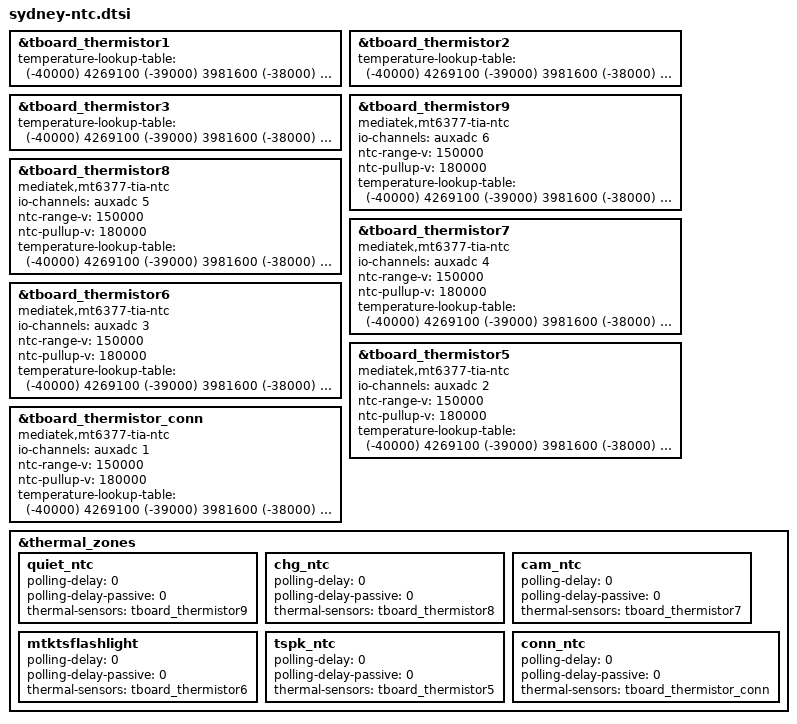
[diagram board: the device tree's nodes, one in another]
/*[TN.NJDC] ntc overlay file.start*/
&tboard_thermistor1 {
	temperature-lookup-table = <
		(-40000) 4269100
		(-39000) 3981600
		(-38000) 3715100
		(-37000) 3468000
		(-36000) 3238600
		(-35000) 3025700
		(-34000) 2827900
		(-33000) 2644200
		(-32000) 2473400
		(-31000) 2314600
		(-30000) 2166900
		(-29000) 2029400
		(-28000) 1901400
		(-27000) 1782200
		(-26000) 1671100
		(-25000) 1567500
		(-24000) 1471000
		(-23000) 1380900
		(-22000) 1296900
		(-21000) 1218400
		(-20000) 1145100
		(-19000) 1076600
		(-18000) 1012600
		(-17000) 952790
		(-16000) 896810
		(-15000) 844440
		(-14000) 795410
		(-13000) 749510
		(-12000) 706500
		(-11000) 666200
		(-10000) 628430
		(-9000) 593000
		(-8000) 559770
		(-7000) 528580
		(-6000) 499300
		(-5000) 471810
		(-4000) 445980
		(-3000) 421710
		(-2000) 398890
		(-1000) 377440
		0 357250
		1000 338260
		2000 320380
		3000 303540
		4000 287680
		5000 272740
		6000 258650
		7000 245370
		8000 232850
		9000 221030
		10000 209870
		11000 199340
		12000 189400
		13000 180010
		14000 171130
		15000 162740
		16000 154800
		17000 147300
		18000 140200
		19000 133480
		20000 127120
		21000 121090
		22000 115390
		23000 109980
		24000 104860
		25000 100000
		26000 95393
		27000 91023
		28000 86877
		29000 82941
		30000 79205
		31000 75656
		32000 72286
		33000 69083
		34000 66039
		35000 63146
		36000 60394
		37000 57776
		38000 55286
		39000 52916
		40000 50660
		41000 48512
		42000 46466
		43000 44517
		44000 42660
		45000 40889
		46000 39202
		47000 37592
		48000 36057
		49000 34592
		50000 33195
		51000 31860
		52000 30587
		53000 29370
		54000 28208
		55000 27098
		56000 26037
		57000 25023
		58000 24053
		59000 23126
		60000 22239
		61000 21390
		62000 20578
		63000 19801
		64000 19056
		65000 18344
		66000 17661
		67000 17007
		68000 16381
		69000 15780
		70000 15205
		71000 14653
		72000 14124
		73000 13616
		74000 13129
		75000 12662
		76000 12213
		77000 11782
		78000 11369
		79000 10972
		80000 10591
		81000 10224
		82000 9872
		83000 9533
		84000 9208
		85000 8895
		86000 8595
		87000 8305
		88000 8027
		89000 7760
		90000 7502
		91000 7254
		92000 7015
		93000 6785
		94000 6564
		95000 6351
		96000 6146
		97000 5948
		98000 5757
		99000 5573
		100000 5396
		101000 5225
		102000 5061
		103000 4902
		104000 4749
		105000 4601
		106000 4458
		107000 4321
		108000 4188
		109000 4059
		110000 3936
		111000 3816
		112000 3700
		113000 3589
		114000 3481
		115000 3377
		116000 3276
		117000 3179
		118000 3085
		119000 2994
		120000 2906
		121000 2821
		122000 2739
		123000 2659
		124000 2582
		125000 2508>;
};
&tboard_thermistor2 {
	temperature-lookup-table = <
		(-40000) 4269100
		(-39000) 3981600
		(-38000) 3715100
		(-37000) 3468000
		(-36000) 3238600
		(-35000) 3025700
		(-34000) 2827900
		(-33000) 2644200
		(-32000) 2473400
		(-31000) 2314600
		(-30000) 2166900
		(-29000) 2029400
		(-28000) 1901400
		(-27000) 1782200
		(-26000) 1671100
		(-25000) 1567500
		(-24000) 1471000
		(-23000) 1380900
		(-22000) 1296900
		(-21000) 1218400
		(-20000) 1145100
		(-19000) 1076600
		(-18000) 1012600
		(-17000) 952790
		(-16000) 896810
		(-15000) 844440
		(-14000) 795410
		(-13000) 749510
		(-12000) 706500
		(-11000) 666200
		(-10000) 628430
		(-9000) 593000
		(-8000) 559770
		(-7000) 528580
		(-6000) 499300
		(-5000) 471810
		(-4000) 445980
		(-3000) 421710
		(-2000) 398890
		(-1000) 377440
		0 357250
		1000 338260
		2000 320380
		3000 303540
		4000 287680
		5000 272740
		6000 258650
		7000 245370
		8000 232850
		9000 221030
		10000 209870
		11000 199340
		12000 189400
		13000 180010
		14000 171130
		15000 162740
		16000 154800
		17000 147300
		18000 140200
		19000 133480
		20000 127120
		21000 121090
		22000 115390
		23000 109980
		24000 104860
		25000 100000
		26000 95393
		27000 91023
		28000 86877
		29000 82941
		30000 79205
		31000 75656
		32000 72286
		33000 69083
		34000 66039
		35000 63146
		36000 60394
		37000 57776
		38000 55286
		39000 52916
		40000 50660
		41000 48512
		42000 46466
		43000 44517
		44000 42660
		45000 40889
		46000 39202
		47000 37592
		48000 36057
		49000 34592
		50000 33195
		51000 31860
		52000 30587
		53000 29370
		54000 28208
		55000 27098
		56000 26037
		57000 25023
		58000 24053
		59000 23126
		60000 22239
		61000 21390
		62000 20578
		63000 19801
		64000 19056
		65000 18344
		66000 17661
		67000 17007
		68000 16381
		69000 15780
		70000 15205
		71000 14653
		72000 14124
		73000 13616
		74000 13129
		75000 12662
		76000 12213
		77000 11782
		78000 11369
		79000 10972
		80000 10591
		81000 10224
		82000 9872
		83000 9533
		84000 9208
		85000 8895
		86000 8595
		87000 8305
		88000 8027
		89000 7760
		90000 7502
		91000 7254
		92000 7015
		93000 6785
		94000 6564
		95000 6351
		96000 6146
		97000 5948
		98000 5757
		99000 5573
		100000 5396
		101000 5225
		102000 5061
		103000 4902
		104000 4749
		105000 4601
		106000 4458
		107000 4321
		108000 4188
		109000 4059
		110000 3936
		111000 3816
		112000 3700
		113000 3589
		114000 3481
		115000 3377
		116000 3276
		117000 3179
		118000 3085
		119000 2994
		120000 2906
		121000 2821
		122000 2739
		123000 2659
		124000 2582
		125000 2508>;
};
&tboard_thermistor3 {
	temperature-lookup-table = <
		(-40000) 4269100
		(-39000) 3981600
		(-38000) 3715100
		(-37000) 3468000
		(-36000) 3238600
		(-35000) 3025700
		(-34000) 2827900
		(-33000) 2644200
		(-32000) 2473400
		(-31000) 2314600
		(-30000) 2166900
		(-29000) 2029400
		(-28000) 1901400
		(-27000) 1782200
		(-26000) 1671100
		(-25000) 1567500
		(-24000) 1471000
		(-23000) 1380900
		(-22000) 1296900
		(-21000) 1218400
		(-20000) 1145100
		(-19000) 1076600
		(-18000) 1012600
		(-17000) 952790
		(-16000) 896810
		(-15000) 844440
		(-14000) 795410
		(-13000) 749510
		(-12000) 706500
		(-11000) 666200
		(-10000) 628430
		(-9000) 593000
		(-8000) 559770
		(-7000) 528580
		(-6000) 499300
		(-5000) 471810
		(-4000) 445980
		(-3000) 421710
		(-2000) 398890
		(-1000) 377440
		0 357250
		1000 338260
		2000 320380
		3000 303540
		4000 287680
		5000 272740
		6000 258650
		7000 245370
		8000 232850
		9000 221030
		10000 209870
		11000 199340
		12000 189400
		13000 180010
		14000 171130
		15000 162740
		16000 154800
		17000 147300
		18000 140200
		19000 133480
		20000 127120
		21000 121090
		22000 115390
		23000 109980
		24000 104860
		25000 100000
		26000 95393
		27000 91023
		28000 86877
		29000 82941
		30000 79205
		31000 75656
		32000 72286
		33000 69083
		34000 66039
		35000 63146
		36000 60394
		37000 57776
		38000 55286
		39000 52916
		40000 50660
		41000 48512
		42000 46466
		43000 44517
		44000 42660
		45000 40889
		46000 39202
		47000 37592
		48000 36057
		49000 34592
		50000 33195
		51000 31860
		52000 30587
		53000 29370
		54000 28208
		55000 27098
		56000 26037
		57000 25023
		58000 24053
		59000 23126
		60000 22239
		61000 21390
		62000 20578
		63000 19801
		64000 19056
		65000 18344
		66000 17661
		67000 17007
		68000 16381
		69000 15780
		70000 15205
		71000 14653
		72000 14124
		73000 13616
		74000 13129
		75000 12662
		76000 12213
		77000 11782
		78000 11369
		79000 10972
		80000 10591
		81000 10224
		82000 9872
		83000 9533
		84000 9208
		85000 8895
		86000 8595
		87000 8305
		88000 8027
		89000 7760
		90000 7502
		91000 7254
		92000 7015
		93000 6785
		94000 6564
		95000 6351
		96000 6146
		97000 5948
		98000 5757
		99000 5573
		100000 5396
		101000 5225
		102000 5061
		103000 4902
		104000 4749
		105000 4601
		106000 4458
		107000 4321
		108000 4188
		109000 4059
		110000 3936
		111000 3816
		112000 3700
		113000 3589
		114000 3481
		115000 3377
		116000 3276
		117000 3179
		118000 3085
		119000 2994
		120000 2906
		121000 2821
		122000 2739
		123000 2659
		124000 2582
		125000 2508>;
};
&tboard_thermistor9 {
	compatible = "mediatek,mt6377-tia-ntc";
	io-channels = <&auxadc 6>;
	io-channel-names = "QUIET_NTC";
	ntc-range-v = <150000>;
	ntc-pullup-v = <180000>;
	#thermal-sensor-cells = <0>;
	temperature-lookup-table = <
		(-40000) 4269100
		(-39000) 3981600
		(-38000) 3715100
		(-37000) 3468000
		(-36000) 3238600
		(-35000) 3025700
		(-34000) 2827900
		(-33000) 2644200
		(-32000) 2473400
		(-31000) 2314600
		(-30000) 2166900
		(-29000) 2029400
		(-28000) 1901400
		(-27000) 1782200
		(-26000) 1671100
		(-25000) 1567500
		(-24000) 1471000
		(-23000) 1380900
		(-22000) 1296900
		(-21000) 1218400
		(-20000) 1145100
		(-19000) 1076600
		(-18000) 1012600
		(-17000) 952790
		(-16000) 896810
		(-15000) 844440
		(-14000) 795410
		(-13000) 749510
		(-12000) 706500
		(-11000) 666200
		(-10000) 628430
		(-9000) 593000
		(-8000) 559770
		(-7000) 528580
		(-6000) 499300
		(-5000) 471810
		(-4000) 445980
		(-3000) 421710
		(-2000) 398890
		(-1000) 377440
		0 357250
		1000 338260
		2000 320380
		3000 303540
		4000 287680
		5000 272740
		6000 258650
		7000 245370
		8000 232850
		9000 221030
		10000 209870
		11000 199340
		12000 189400
		13000 180010
		14000 171130
		15000 162740
		16000 154800
		17000 147300
		18000 140200
		19000 133480
		20000 127120
		21000 121090
		22000 115390
		23000 109980
		24000 104860
		25000 100000
		26000 95393
		27000 91023
		28000 86877
		29000 82941
		30000 79205
		31000 75656
		32000 72286
		33000 69083
		34000 66039
		35000 63146
		36000 60394
		37000 57776
		38000 55286
		39000 52916
		40000 50660
		41000 48512
		42000 46466
		43000 44517
		44000 42660
		45000 40889
		46000 39202
		47000 37592
		48000 36057
		49000 34592
		50000 33195
		51000 31860
		52000 30587
		53000 29370
		54000 28208
		55000 27098
		56000 26037
		57000 25023
		58000 24053
		59000 23126
		60000 22239
		61000 21390
		62000 20578
		63000 19801
		64000 19056
		65000 18344
		66000 17661
		67000 17007
		68000 16381
		69000 15780
		70000 15205
		71000 14653
		72000 14124
		73000 13616
		74000 13129
		75000 12662
		76000 12213
		77000 11782
		78000 11369
		79000 10972
		80000 10591
		81000 10224
		82000 9872
		83000 9533
		84000 9208
		85000 8895
		86000 8595
		87000 8305
		88000 8027
		89000 7760
		90000 7502
		91000 7254
		92000 7015
		93000 6785
		94000 6564
		95000 6351
		96000 6146
		97000 5948
		98000 5757
		99000 5573
		100000 5396
		101000 5225
		102000 5061
		103000 4902
		104000 4749
		105000 4601
		106000 4458
		107000 4321
		108000 4188
		109000 4059
		110000 3936
		111000 3816
		112000 3700
		113000 3589
		114000 3481
		115000 3377
		116000 3276
		117000 3179
		118000 3085
		119000 2994
		120000 2906
		121000 2821
		122000 2739
		123000 2659
		124000 2582
		125000 2508>;
};
&tboard_thermistor8 {
	compatible = "mediatek,mt6377-tia-ntc";
	io-channels = <&auxadc 5>;
	io-channel-names = "CHG_NTC";
	ntc-range-v = <150000>;
	ntc-pullup-v = <180000>;
	#thermal-sensor-cells = <0>;
	temperature-lookup-table = <
		(-40000) 4269100
		(-39000) 3981600
		(-38000) 3715100
		(-37000) 3468000
		(-36000) 3238600
		(-35000) 3025700
		(-34000) 2827900
		(-33000) 2644200
		(-32000) 2473400
		(-31000) 2314600
		(-30000) 2166900
		(-29000) 2029400
		(-28000) 1901400
		(-27000) 1782200
		(-26000) 1671100
		(-25000) 1567500
		(-24000) 1471000
		(-23000) 1380900
		(-22000) 1296900
		(-21000) 1218400
		(-20000) 1145100
		(-19000) 1076600
		(-18000) 1012600
		(-17000) 952790
		(-16000) 896810
		(-15000) 844440
		(-14000) 795410
		(-13000) 749510
		(-12000) 706500
		(-11000) 666200
		(-10000) 628430
		(-9000) 593000
		(-8000) 559770
		(-7000) 528580
		(-6000) 499300
		(-5000) 471810
		(-4000) 445980
		(-3000) 421710
		(-2000) 398890
		(-1000) 377440
		0 357250
		1000 338260
		2000 320380
		3000 303540
		4000 287680
		5000 272740
		6000 258650
		7000 245370
		8000 232850
		9000 221030
		10000 209870
		11000 199340
		12000 189400
		13000 180010
		14000 171130
		15000 162740
		16000 154800
		17000 147300
		18000 140200
		19000 133480
		20000 127120
		21000 121090
		22000 115390
		23000 109980
		24000 104860
		25000 100000
		26000 95393
		27000 91023
		28000 86877
		29000 82941
		30000 79205
		31000 75656
		32000 72286
		33000 69083
		34000 66039
		35000 63146
		36000 60394
		37000 57776
		38000 55286
		39000 52916
		40000 50660
		41000 48512
		42000 46466
		43000 44517
		44000 42660
		45000 40889
		46000 39202
		47000 37592
		48000 36057
		49000 34592
		50000 33195
		51000 31860
		52000 30587
		53000 29370
		54000 28208
		55000 27098
		56000 26037
		57000 25023
		58000 24053
		59000 23126
		60000 22239
		61000 21390
		62000 20578
		63000 19801
		64000 19056
		65000 18344
		66000 17661
		67000 17007
		68000 16381
		69000 15780
		70000 15205
		71000 14653
		72000 14124
		73000 13616
		74000 13129
		75000 12662
		76000 12213
		77000 11782
		78000 11369
		79000 10972
		80000 10591
		81000 10224
		82000 9872
		83000 9533
		84000 9208
		85000 8895
		86000 8595
		87000 8305
		88000 8027
		89000 7760
		90000 7502
		91000 7254
		92000 7015
		93000 6785
		94000 6564
		95000 6351
		96000 6146
		97000 5948
		98000 5757
		99000 5573
		100000 5396
		101000 5225
		102000 5061
		103000 4902
		104000 4749
		105000 4601
		106000 4458
		107000 4321
		108000 4188
		109000 4059
		110000 3936
		111000 3816
		112000 3700
		113000 3589
		114000 3481
		115000 3377
		116000 3276
		117000 3179
		118000 3085
		119000 2994
		120000 2906
		121000 2821
		122000 2739
		123000 2659
		124000 2582
		125000 2508>;
};
&tboard_thermistor7 {
	compatible = "mediatek,mt6377-tia-ntc";
	io-channels = <&auxadc 4>;
	io-channel-names = "CAM_NTC";
	ntc-range-v = <150000>;
	ntc-pullup-v = <180000>;
	#thermal-sensor-cells = <0>;
	temperature-lookup-table = <
		(-40000) 4269100
		(-39000) 3981600
		(-38000) 3715100
		(-37000) 3468000
		(-36000) 3238600
		(-35000) 3025700
		(-34000) 2827900
		(-33000) 2644200
		(-32000) 2473400
		(-31000) 2314600
		(-30000) 2166900
		(-29000) 2029400
		(-28000) 1901400
		(-27000) 1782200
		(-26000) 1671100
		(-25000) 1567500
		(-24000) 1471000
		(-23000) 1380900
		(-22000) 1296900
		(-21000) 1218400
		(-20000) 1145100
		(-19000) 1076600
		(-18000) 1012600
		(-17000) 952790
		(-16000) 896810
		(-15000) 844440
		(-14000) 795410
		(-13000) 749510
		(-12000) 706500
		(-11000) 666200
		(-10000) 628430
		(-9000) 593000
		(-8000) 559770
		(-7000) 528580
		(-6000) 499300
		(-5000) 471810
		(-4000) 445980
		(-3000) 421710
		(-2000) 398890
		(-1000) 377440
		0 357250
		1000 338260
		2000 320380
		3000 303540
		4000 287680
		5000 272740
		6000 258650
		7000 245370
		8000 232850
		9000 221030
		10000 209870
		11000 199340
		12000 189400
		13000 180010
		14000 171130
		15000 162740
		16000 154800
		17000 147300
		18000 140200
		19000 133480
		20000 127120
		21000 121090
		22000 115390
		23000 109980
		24000 104860
		25000 100000
		26000 95393
		27000 91023
		28000 86877
		29000 82941
		30000 79205
		31000 75656
		32000 72286
		33000 69083
		34000 66039
		35000 63146
		36000 60394
		37000 57776
		38000 55286
		39000 52916
		40000 50660
		41000 48512
		42000 46466
		43000 44517
		44000 42660
		45000 40889
		46000 39202
		47000 37592
		48000 36057
		49000 34592
		50000 33195
		51000 31860
		52000 30587
		53000 29370
		54000 28208
		55000 27098
		56000 26037
		57000 25023
		58000 24053
		59000 23126
		60000 22239
		61000 21390
		62000 20578
		63000 19801
		64000 19056
		65000 18344
		66000 17661
		67000 17007
		68000 16381
		69000 15780
		70000 15205
		71000 14653
		72000 14124
		73000 13616
		74000 13129
		75000 12662
		76000 12213
		77000 11782
		78000 11369
		79000 10972
		80000 10591
		81000 10224
		82000 9872
		83000 9533
		84000 9208
		85000 8895
		86000 8595
		87000 8305
		88000 8027
		89000 7760
		90000 7502
		91000 7254
		92000 7015
		93000 6785
		94000 6564
		95000 6351
		96000 6146
		97000 5948
		98000 5757
		99000 5573
		100000 5396
		101000 5225
		102000 5061
		103000 4902
		104000 4749
		105000 4601
		106000 4458
		107000 4321
		108000 4188
		109000 4059
		110000 3936
		111000 3816
		112000 3700
		113000 3589
		114000 3481
		115000 3377
		116000 3276
		117000 3179
		118000 3085
		119000 2994
		120000 2906
		121000 2821
		122000 2739
		123000 2659
		124000 2582
		125000 2508>;
};
&tboard_thermistor6 {
	compatible = "mediatek,mt6377-tia-ntc";
	io-channels = <&auxadc 3>;
	io-channel-names = "FLASH_NTC";
	ntc-range-v = <150000>;
	ntc-pullup-v = <180000>;
	#thermal-sensor-cells = <0>;
	temperature-lookup-table = <
		(-40000) 4269100
		(-39000) 3981600
		(-38000) 3715100
		(-37000) 3468000
		(-36000) 3238600
		(-35000) 3025700
		(-34000) 2827900
		(-33000) 2644200
		(-32000) 2473400
		(-31000) 2314600
		(-30000) 2166900
		(-29000) 2029400
		(-28000) 1901400
		(-27000) 1782200
		(-26000) 1671100
		(-25000) 1567500
		(-24000) 1471000
		(-23000) 1380900
		(-22000) 1296900
		(-21000) 1218400
		(-20000) 1145100
		(-19000) 1076600
		(-18000) 1012600
		(-17000) 952790
		(-16000) 896810
		(-15000) 844440
		(-14000) 795410
		(-13000) 749510
		(-12000) 706500
		(-11000) 666200
		(-10000) 628430
		(-9000) 593000
		(-8000) 559770
		(-7000) 528580
		(-6000) 499300
		(-5000) 471810
		(-4000) 445980
		(-3000) 421710
		(-2000) 398890
		(-1000) 377440
		0 357250
		1000 338260
		2000 320380
		3000 303540
		4000 287680
		5000 272740
		6000 258650
		7000 245370
		8000 232850
		9000 221030
		10000 209870
		11000 199340
		12000 189400
		13000 180010
		14000 171130
		15000 162740
		16000 154800
		17000 147300
		18000 140200
		19000 133480
		20000 127120
		21000 121090
		22000 115390
		23000 109980
		24000 104860
		25000 100000
		26000 95393
		27000 91023
		28000 86877
		29000 82941
		30000 79205
		31000 75656
		32000 72286
		33000 69083
		34000 66039
		35000 63146
		36000 60394
		37000 57776
		38000 55286
		39000 52916
		40000 50660
		41000 48512
		42000 46466
		43000 44517
		44000 42660
		45000 40889
		46000 39202
		47000 37592
		48000 36057
		49000 34592
		50000 33195
		51000 31860
		52000 30587
		53000 29370
		54000 28208
		55000 27098
		56000 26037
		57000 25023
		58000 24053
		59000 23126
		60000 22239
		61000 21390
		62000 20578
		63000 19801
		64000 19056
		65000 18344
		66000 17661
		67000 17007
		68000 16381
		69000 15780
		70000 15205
		71000 14653
		72000 14124
		73000 13616
		74000 13129
		75000 12662
		76000 12213
		77000 11782
		78000 11369
		79000 10972
		80000 10591
		81000 10224
		82000 9872
		83000 9533
		84000 9208
		85000 8895
		86000 8595
		87000 8305
		88000 8027
		89000 7760
		90000 7502
		91000 7254
		92000 7015
		93000 6785
		94000 6564
		95000 6351
		96000 6146
		97000 5948
		98000 5757
		99000 5573
		100000 5396
		101000 5225
		102000 5061
		103000 4902
		104000 4749
		105000 4601
		106000 4458
		107000 4321
		108000 4188
		109000 4059
		110000 3936
		111000 3816
		112000 3700
		113000 3589
		114000 3481
		115000 3377
		116000 3276
		117000 3179
		118000 3085
		119000 2994
		120000 2906
		121000 2821
		122000 2739
		123000 2659
		124000 2582
		125000 2508>;
};
&tboard_thermistor5 {
	compatible = "mediatek,mt6377-tia-ntc";
	io-channels = <&auxadc 2>;
	io-channel-names = "SPK_NTC";
	ntc-range-v = <150000>;
	ntc-pullup-v = <180000>;
	#thermal-sensor-cells = <0>;
	temperature-lookup-table = <
		(-40000) 4269100
		(-39000) 3981600
		(-38000) 3715100
		(-37000) 3468000
		(-36000) 3238600
		(-35000) 3025700
		(-34000) 2827900
		(-33000) 2644200
		(-32000) 2473400
		(-31000) 2314600
		(-30000) 2166900
		(-29000) 2029400
		(-28000) 1901400
		(-27000) 1782200
		(-26000) 1671100
		(-25000) 1567500
		(-24000) 1471000
		(-23000) 1380900
		(-22000) 1296900
		(-21000) 1218400
		(-20000) 1145100
		(-19000) 1076600
		(-18000) 1012600
		(-17000) 952790
		(-16000) 896810
		(-15000) 844440
		(-14000) 795410
		(-13000) 749510
		(-12000) 706500
		(-11000) 666200
		(-10000) 628430
		(-9000) 593000
		(-8000) 559770
		(-7000) 528580
		(-6000) 499300
		(-5000) 471810
		(-4000) 445980
		(-3000) 421710
		(-2000) 398890
		(-1000) 377440
		0 357250
		1000 338260
		2000 320380
		3000 303540
		4000 287680
		5000 272740
		6000 258650
		7000 245370
		8000 232850
		9000 221030
		10000 209870
		11000 199340
		12000 189400
		13000 180010
		14000 171130
		15000 162740
		16000 154800
		17000 147300
		18000 140200
		19000 133480
		20000 127120
		21000 121090
		22000 115390
		23000 109980
		24000 104860
		25000 100000
		26000 95393
		27000 91023
		28000 86877
		29000 82941
		30000 79205
		31000 75656
		32000 72286
		33000 69083
		34000 66039
		35000 63146
		36000 60394
		37000 57776
		38000 55286
		39000 52916
		40000 50660
		41000 48512
		42000 46466
		43000 44517
		44000 42660
		45000 40889
		46000 39202
		47000 37592
		48000 36057
		49000 34592
		50000 33195
		51000 31860
		52000 30587
		53000 29370
		54000 28208
		55000 27098
		56000 26037
		57000 25023
		58000 24053
		59000 23126
		60000 22239
		61000 21390
		62000 20578
		63000 19801
		64000 19056
		65000 18344
		66000 17661
		67000 17007
		68000 16381
		69000 15780
		70000 15205
		71000 14653
		72000 14124
		73000 13616
		74000 13129
		75000 12662
		76000 12213
		77000 11782
		78000 11369
		79000 10972
		80000 10591
		81000 10224
		82000 9872
		83000 9533
		84000 9208
		85000 8895
		86000 8595
		87000 8305
		88000 8027
		89000 7760
		90000 7502
		91000 7254
		92000 7015
		93000 6785
		94000 6564
		95000 6351
		96000 6146
		97000 5948
		98000 5757
		99000 5573
		100000 5396
		101000 5225
		102000 5061
		103000 4902
		104000 4749
		105000 4601
		106000 4458
		107000 4321
		108000 4188
		109000 4059
		110000 3936
		111000 3816
		112000 3700
		113000 3589
		114000 3481
		115000 3377
		116000 3276
		117000 3179
		118000 3085
		119000 2994
		120000 2906
		121000 2821
		122000 2739
		123000 2659
		124000 2582
		125000 2508>;
};
&tboard_thermistor_conn {
	compatible = "mediatek,mt6377-tia-ntc";
	io-channels = <&auxadc 1>;
	io-channel-names = "CONN_NTC";
	ntc-range-v = <150000>;
	ntc-pullup-v = <180000>;
	#thermal-sensor-cells = <0>;
	temperature-lookup-table = <
		(-40000) 4269100
		(-39000) 3981600
		(-38000) 3715100
		(-37000) 3468000
		(-36000) 3238600
		(-35000) 3025700
		(-34000) 2827900
		(-33000) 2644200
		(-32000) 2473400
		(-31000) 2314600
		(-30000) 2166900
		(-29000) 2029400
		(-28000) 1901400
		(-27000) 1782200
		(-26000) 1671100
		(-25000) 1567500
		(-24000) 1471000
		(-23000) 1380900
		(-22000) 1296900
		(-21000) 1218400
		(-20000) 1145100
		(-19000) 1076600
		(-18000) 1012600
		(-17000) 952790
		(-16000) 896810
		(-15000) 844440
		(-14000) 795410
		(-13000) 749510
		(-12000) 706500
		(-11000) 666200
		(-10000) 628430
		(-9000) 593000
		(-8000) 559770
		(-7000) 528580
		(-6000) 499300
		(-5000) 471810
		(-4000) 445980
		(-3000) 421710
		(-2000) 398890
		(-1000) 377440
		0 357250
		1000 338260
		2000 320380
		3000 303540
		4000 287680
		5000 272740
		6000 258650
		7000 245370
		8000 232850
		9000 221030
		10000 209870
		11000 199340
		12000 189400
		13000 180010
		14000 171130
		15000 162740
		16000 154800
		17000 147300
		18000 140200
		19000 133480
		20000 127120
		21000 121090
		22000 115390
		23000 109980
		24000 104860
		25000 100000
		26000 95393
		27000 91023
		28000 86877
		29000 82941
		30000 79205
		31000 75656
		32000 72286
		33000 69083
		34000 66039
		35000 63146
		36000 60394
		37000 57776
		38000 55286
		39000 52916
		40000 50660
		41000 48512
		42000 46466
		43000 44517
		44000 42660
		45000 40889
		46000 39202
		47000 37592
		48000 36057
		49000 34592
		50000 33195
		51000 31860
		52000 30587
		53000 29370
		54000 28208
		55000 27098
		56000 26037
		57000 25023
		58000 24053
		59000 23126
		60000 22239
		61000 21390
		62000 20578
		63000 19801
		64000 19056
		65000 18344
		66000 17661
		67000 17007
		68000 16381
		69000 15780
		70000 15205
		71000 14653
		72000 14124
		73000 13616
		74000 13129
		75000 12662
		76000 12213
		77000 11782
		78000 11369
		79000 10972
		80000 10591
		81000 10224
		82000 9872
		83000 9533
		84000 9208
		85000 8895
		86000 8595
		87000 8305
		88000 8027
		89000 7760
		90000 7502
		91000 7254
		92000 7015
		93000 6785
		94000 6564
		95000 6351
		96000 6146
		97000 5948
		98000 5757
		99000 5573
		100000 5396
		101000 5225
		102000 5061
		103000 4902
		104000 4749
		105000 4601
		106000 4458
		107000 4321
		108000 4188
		109000 4059
		110000 3936
		111000 3816
		112000 3700
		113000 3589
		114000 3481
		115000 3377
		116000 3276
		117000 3179
		118000 3085
		119000 2994
		120000 2906
		121000 2821
		122000 2739
		123000 2659
		124000 2582
		125000 2508>;
};


&thermal_zones {
	quiet_ntc: quiet_ntc {
		polling-delay = <0>; /* milliseconds */
		polling-delay-passive = <0>; /* milliseconds */
		thermal-sensors = <&tboard_thermistor9>;
	};
	chg_ntc: chg_ntc {
		polling-delay = <0>; /* milliseconds */
		polling-delay-passive = <0>; /* milliseconds */
		thermal-sensors = <&tboard_thermistor8>;
	};
	cam_ntc: cam_ntc {
		polling-delay = <0>; /* milliseconds */
		polling-delay-passive = <0>; /* milliseconds */
		thermal-sensors = <&tboard_thermistor7>;
	};
	mtktsflashlight: mtktsflashlight {
		polling-delay = <0>; /* milliseconds */
		polling-delay-passive = <0>; /* milliseconds */
		thermal-sensors = <&tboard_thermistor6>;
	};
	tspk_ntc: tspk_ntc {
		polling-delay = <0>; /* milliseconds */
		polling-delay-passive = <0>; /* milliseconds */
		thermal-sensors = <&tboard_thermistor5>;
	};
	conn_ntc: conn_ntc {
		polling-delay = <0>; /* milliseconds */
		polling-delay-passive = <0>; /* milliseconds */
		thermal-sensors = <&tboard_thermistor_conn>;
	};
};
/*[TN.NJDC] ntc overlay file.end*/
